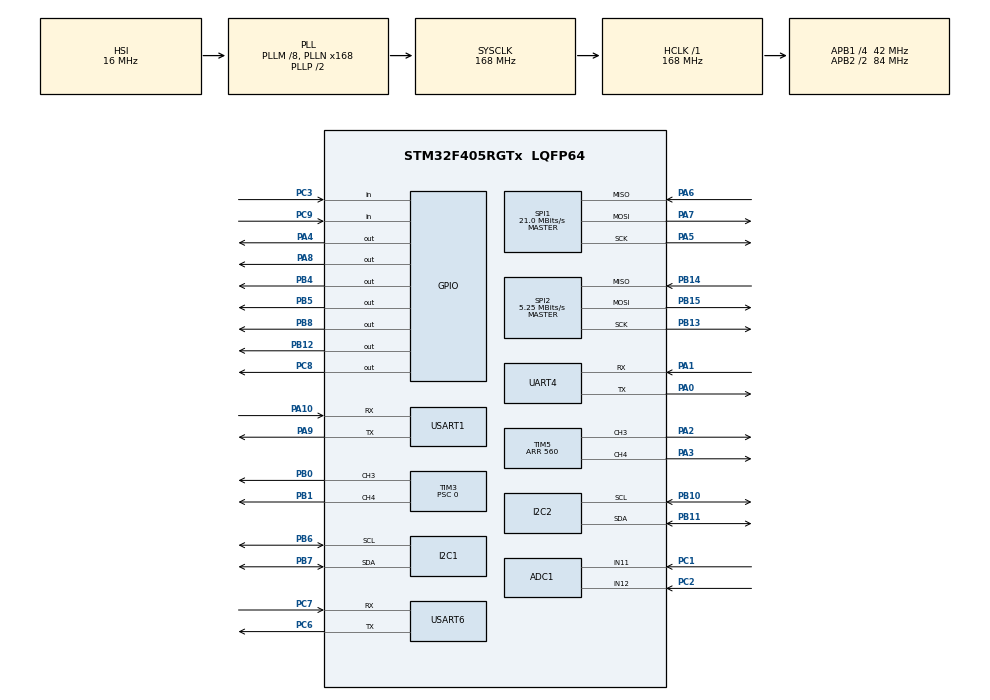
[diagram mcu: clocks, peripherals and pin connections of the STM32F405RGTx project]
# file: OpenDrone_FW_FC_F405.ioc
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ADC1.Channel-0\#ChannelRegularConversion=ADC_CHANNEL_11
ADC1.NbrOfConversionFlag=1
ADC1.Rank-0\#ChannelRegularConversion=1
ADC1.SamplingTime-0\#ChannelRegularConversion=ADC_SAMPLETIME_3CYCLES
ADC1.master=1
Dma.Request0=TIM5_CH4/TRIG
Dma.Request1=TIM3_CH3
Dma.Request2=TIM3_CH4/UP
Dma.Request3=TIM5_CH3/UP
Dma.TIM3_CH3.1.Direction=DMA_MEMORY_TO_PERIPH
Dma.TIM3_CH3.1.FIFOMode=DMA_FIFOMODE_DISABLE
Dma.TIM3_CH3.1.Instance=DMA1_Stream7
Dma.TIM3_CH3.1.MemDataAlignment=DMA_MDATAALIGN_WORD
Dma.TIM3_CH3.1.MemInc=DMA_MINC_ENABLE
Dma.TIM3_CH3.1.Mode=DMA_NORMAL
Dma.TIM3_CH3.1.PeriphDataAlignment=DMA_PDATAALIGN_WORD
Dma.TIM3_CH3.1.PeriphInc=DMA_PINC_DISABLE
Dma.TIM3_CH3.1.Priority=DMA_PRIORITY_HIGH
Dma.TIM3_CH4/UP.2.Direction=DMA_MEMORY_TO_PERIPH
Dma.TIM3_CH4/UP.2.FIFOMode=DMA_FIFOMODE_DISABLE
Dma.TIM3_CH4/UP.2.Instance=DMA1_Stream2
Dma.TIM3_CH4/UP.2.MemDataAlignment=DMA_MDATAALIGN_WORD
Dma.TIM3_CH4/UP.2.MemInc=DMA_MINC_ENABLE
Dma.TIM3_CH4/UP.2.Mode=DMA_NORMAL
Dma.TIM3_CH4/UP.2.PeriphDataAlignment=DMA_PDATAALIGN_WORD
Dma.TIM3_CH4/UP.2.PeriphInc=DMA_PINC_DISABLE
Dma.TIM3_CH4/UP.2.Priority=DMA_PRIORITY_HIGH
Dma.TIM5_CH3/UP.3.Direction=DMA_MEMORY_TO_PERIPH
Dma.TIM5_CH3/UP.3.FIFOMode=DMA_FIFOMODE_DISABLE
Dma.TIM5_CH3/UP.3.Instance=DMA1_Stream0
Dma.TIM5_CH3/UP.3.MemDataAlignment=DMA_MDATAALIGN_WORD
Dma.TIM5_CH3/UP.3.MemInc=DMA_MINC_ENABLE
Dma.TIM5_CH3/UP.3.Mode=DMA_NORMAL
Dma.TIM5_CH3/UP.3.PeriphDataAlignment=DMA_PDATAALIGN_WORD
Dma.TIM5_CH3/UP.3.PeriphInc=DMA_PINC_DISABLE
Dma.TIM5_CH3/UP.3.Priority=DMA_PRIORITY_HIGH
Dma.TIM5_CH4/TRIG.0.Direction=DMA_MEMORY_TO_PERIPH
Dma.TIM5_CH4/TRIG.0.FIFOMode=DMA_FIFOMODE_DISABLE
Dma.TIM5_CH4/TRIG.0.Instance=DMA1_Stream3
Dma.TIM5_CH4/TRIG.0.MemDataAlignment=DMA_MDATAALIGN_WORD
Dma.TIM5_CH4/TRIG.0.MemInc=DMA_MINC_ENABLE
Dma.TIM5_CH4/TRIG.0.Mode=DMA_NORMAL
Dma.TIM5_CH4/TRIG.0.PeriphDataAlignment=DMA_PDATAALIGN_WORD
Dma.TIM5_CH4/TRIG.0.PeriphInc=DMA_PINC_DISABLE
Dma.TIM5_CH4/TRIG.0.Priority=DMA_PRIORITY_HIGH
Mcu.Family=STM32F4
Mcu.Name=STM32F405RGTx
Mcu.Package=LQFP64
NVIC.DMA1_Stream0_IRQn=true\:0\:0\:false\:false\:true\:false\:true\:true
NVIC.DMA1_Stream2_IRQn=true\:0\:0\:false\:false\:true\:false\:true\:true
NVIC.DMA1_Stream3_IRQn=true\:0\:0\:false\:false\:true\:false\:true\:true
NVIC.DMA1_Stream7_IRQn=true\:0\:0\:false\:false\:true\:false\:true\:true
NVIC.PriorityGroup=NVIC_PRIORITYGROUP_4
PA0-WKUP.Mode=Asynchronous
PA0-WKUP.Signal=UART4_TX
PA1.Mode=Asynchronous
PA1.Signal=UART4_RX
PA10.Mode=Asynchronous
PA10.Signal=USART1_RX
PA2.Signal=S_TIM5_CH3
PA3.Signal=S_TIM5_CH4
PA4.GPIO_Speed=GPIO_SPEED_FREQ_HIGH
PA4.PinState=GPIO_PIN_SET
PA4.Signal=GPIO_Output
PA5.Mode=Full_Duplex_Master
PA5.Signal=SPI1_SCK
PA6.Mode=Full_Duplex_Master
PA6.Signal=SPI1_MISO
PA7.Mode=Full_Duplex_Master
PA7.Signal=SPI1_MOSI
PA8.Signal=GPIO_Output
PA9.Mode=Asynchronous
PA9.Signal=USART1_TX
PB0.Signal=S_TIM3_CH3
PB1.Signal=S_TIM3_CH4
PB10.Mode=I2C
PB10.Signal=I2C2_SCL
PB11.Mode=I2C
PB11.Signal=I2C2_SDA
PB12.Signal=GPIO_Output
PB13.Mode=Full_Duplex_Master
PB13.Signal=SPI2_SCK
PB14.Mode=Full_Duplex_Master
PB14.Signal=SPI2_MISO
PB15.Mode=Full_Duplex_Master
PB15.Signal=SPI2_MOSI
PB4.Signal=GPIO_Output
PB5.Signal=GPIO_Output
PB6.Mode=I2C
PB6.Signal=I2C1_SCL
PB7.Mode=I2C
PB7.Signal=I2C1_SDA
PB8.Signal=GPIO_Output
PC1.Signal=ADCx_IN11
PC2.Signal=ADCx_IN12
PC3.Signal=GPIO_Input
PC6.Mode=Asynchronous
PC6.Signal=USART6_TX
PC7.Mode=Asynchronous
PC7.Signal=USART6_RX
PC8.Signal=GPIO_Output
PC9.GPIO_PuPd=GPIO_PULLUP
PC9.Signal=GPIO_Input
PH0-OSC_IN.Mode=HSE-External-Oscillator
PH0-OSC_IN.Signal=RCC_OSC_IN
PH1-OSC_OUT.Mode=HSE-External-Oscillator
PH1-OSC_OUT.Signal=RCC_OSC_OUT
ProjectManager.HeapSize=0x200
ProjectManager.StackSize=0x400
ProjectManager.TargetToolchain=STM32CubeIDE
RCC.48MHZClocksFreq_Value=84000000
RCC.AHBFreq_Value=168000000
RCC.APB1CLKDivider=RCC_HCLK_DIV4
RCC.APB1Freq_Value=42000000
RCC.APB1TimFreq_Value=84000000
RCC.APB2CLKDivider=RCC_HCLK_DIV2
RCC.APB2Freq_Value=84000000
RCC.APB2TimFreq_Value=168000000
RCC.CortexFreq_Value=168000000
RCC.HCLKFreq_Value=168000000
RCC.HSE_VALUE=8000000
RCC.HSI_VALUE=16000000
RCC.LSE_VALUE=32768
RCC.PLLM=8
RCC.PLLN=168
RCC.SYSCLKFreq_VALUE=168000000
RCC.SYSCLKSource=RCC_SYSCLKSOURCE_PLLCLK
RCC.VCOOutputFreq_Value=336000000
SH.ADCx_IN11.0=ADC1_IN11,IN11
SH.ADCx_IN12.0=ADC1_IN12,IN12
SH.S_TIM3_CH3.0=TIM3_CH3,PWM Generation3 CH3
SH.S_TIM3_CH4.0=TIM3_CH4,PWM Generation4 CH4
SH.S_TIM5_CH3.0=TIM5_CH3,PWM Generation3 CH3
SH.S_TIM5_CH4.0=TIM5_CH4,PWM Generation4 CH4
SPI1.BaudRatePrescaler=SPI_BAUDRATEPRESCALER_4
SPI1.CLKPhase=SPI_PHASE_2EDGE
SPI1.CLKPolarity=SPI_POLARITY_HIGH
SPI1.CRCCalculation=SPI_CRCCALCULATION_DISABLE
SPI1.CalculateBaudRate=21.0 MBits/s
SPI1.Direction=SPI_DIRECTION_2LINES
SPI1.Mode=SPI_MODE_MASTER
SPI1.VirtualType=VM_MASTER
SPI2.BaudRatePrescaler=SPI_BAUDRATEPRESCALER_8
SPI2.CalculateBaudRate=5.25 MBits/s
SPI2.Direction=SPI_DIRECTION_2LINES
SPI2.Mode=SPI_MODE_MASTER
SPI2.VirtualType=VM_MASTER
TIM2.AutoReloadPreload=TIM_AUTORELOAD_PRELOAD_ENABLE
TIM2.Prescaler=83
TIM3.AutoReloadPreload=TIM_AUTORELOAD_PRELOAD_ENABLE
TIM3.Channel-PWM\ Generation3\ CH3=TIM_CHANNEL_3
TIM3.Channel-PWM\ Generation4\ CH4=TIM_CHANNEL_4
TIM3.Period=560
TIM3.Prescaler=0
TIM5.Channel-PWM\ Generation3\ CH3=TIM_CHANNEL_3
TIM5.Channel-PWM\ Generation4\ CH4=TIM_CHANNEL_4
TIM5.Period=560
UART4.VirtualMode=Asynchronous
USART1.VirtualMode=VM_ASYNC
USART6.VirtualMode=VM_ASYNC
VP_TIM2_VS_ClockSourceINT.Mode=Internal
VP_TIM3_VS_ClockSourceINT.Mode=Internal
board=custom

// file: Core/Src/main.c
/* USER CODE BEGIN Header */
/**
 ******************************************************************************
 * @file           : main.c
 * @brief          : Main program body
 ******************************************************************************
 * @attention
 *
 * Copyright (c) 2024 STMicroelectronics.
 * All rights reserved.
 *
 * This software is licensed under terms that can be found in the LICENSE file
 * in the root directory of this software component.
 * If no LICENSE file comes with this software, it is provided AS-IS.
 *
 ******************************************************************************
 */
/* USER CODE END Header */
#include "main.h"
#include "adc.h"
#include "dma.h"
#include "i2c.h"
#include "spi.h"
#include "tim.h"
#include "usart.h"
#include "gpio.h"

/* USER CODE BEGIN Includes */
#include "OpenDrone_FC.h"
/* USER CODE END Includes */

void SystemClock_Config(void);

int main(void)
{

  /* MCU Configuration--------------------------------------------------------*/

  /* Reset of all peripherals, Initializes the Flash interface and the Systick. */
  HAL_Init();

  /* Configure the system clock */
  SystemClock_Config();

  /* Initialize all configured peripherals */
  MX_GPIO_Init();
  MX_DMA_Init();
  MX_SPI2_Init();
  MX_I2C1_Init();
  MX_TIM3_Init();
  MX_USART1_UART_Init();
  MX_I2C2_Init();
  MX_UART4_Init();
  MX_ADC1_Init();
  MX_SPI1_Init();
  MX_USART6_UART_Init();
  MX_TIM5_Init();
  MX_TIM2_Init();
  /* USER CODE BEGIN 2 */
  HAL_TIM_Base_Start(&htim2);

  OpenDrone_FC_Init();
  /* USER CODE END 2 */

  /* Infinite loop */
  /* USER CODE BEGIN WHILE */
  while (1) {
    OpenDrone_FC_Main();
    /* USER CODE END WHILE */

  }
}

void SystemClock_Config(void)
{
  RCC_OscInitTypeDef RCC_OscInitStruct = {0};
  RCC_ClkInitTypeDef RCC_ClkInitStruct = {0};

  /** Configure the main internal regulator output voltage
  */
  __HAL_RCC_PWR_CLK_ENABLE();
  __HAL_PWR_VOLTAGESCALING_CONFIG(PWR_REGULATOR_VOLTAGE_SCALE1);

  /** Initializes the RCC Oscillators according to the specified parameters
  * in the RCC_OscInitTypeDef structure.
  */
  RCC_OscInitStruct.OscillatorType = RCC_OSCILLATORTYPE_HSI;
  RCC_OscInitStruct.HSIState = RCC_HSI_ON;
  RCC_OscInitStruct.HSICalibrationValue = RCC_HSICALIBRATION_DEFAULT;
  RCC_OscInitStruct.PLL.PLLState = RCC_PLL_ON;
  RCC_OscInitStruct.PLL.PLLSource = RCC_PLLSOURCE_HSI;
  RCC_OscInitStruct.PLL.PLLM = 8;
  RCC_OscInitStruct.PLL.PLLN = 168;
  RCC_OscInitStruct.PLL.PLLP = RCC_PLLP_DIV2;
  RCC_OscInitStruct.PLL.PLLQ = 4;
  if (HAL_RCC_OscConfig(&RCC_OscInitStruct) != HAL_OK)
  {
    Error_Handler();
  }

  /** Initializes the CPU, AHB and APB buses clocks
  */
  RCC_ClkInitStruct.ClockType = RCC_CLOCKTYPE_HCLK|RCC_CLOCKTYPE_SYSCLK
                              |RCC_CLOCKTYPE_PCLK1|RCC_CLOCKTYPE_PCLK2;
  RCC_ClkInitStruct.SYSCLKSource = RCC_SYSCLKSOURCE_PLLCLK;
  RCC_ClkInitStruct.AHBCLKDivider = RCC_SYSCLK_DIV1;
  RCC_ClkInitStruct.APB1CLKDivider = RCC_HCLK_DIV4;
  RCC_ClkInitStruct.APB2CLKDivider = RCC_HCLK_DIV2;

  if (HAL_RCC_ClockConfig(&RCC_ClkInitStruct, FLASH_LATENCY_5) != HAL_OK)
  {
    Error_Handler();
  }
}

void Error_Handler(void)
{
  __disable_irq();
  while (1) {
  }
}
#ifdef USE_FULL_ASSERT
/**
  * @brief  Reports the name of the source file and the source line number
  *         where the assert_param error has occurred.
  * @param  file: pointer to the source file name
  * @param  line: assert_param error line source number
  * @retval None
  */
void assert_failed(uint8_t *file, uint32_t line)
{
  /* USER CODE BEGIN 6 */
  /* User can add his own implementation to report the file name and line
     number,
     ex: printf("Wrong parameters value: file %s on line %d\r\n", file, line) */
  /* USER CODE END 6 */
}
#endif /* USE_FULL_ASSERT */
